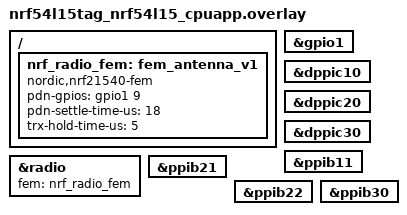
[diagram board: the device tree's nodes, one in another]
/*
 * Copyright (c) 2026 Nordic Semiconductor ASA
 *
 * SPDX-License-Identifier: LicenseRef-Nordic-5-Clause
 */

/*
 * Drive the SKY13348 antenna switch V1 line from MPSL instead of holding it
 * statically high, so it is only asserted around radio TX/RX windows.
 *
 * The nRF21540 FEM driver is reused here purely for its PDN pin, which is the
 * only FEM output asserted for both TX and RX. No nRF21540 is present, so the
 * PA/LNA pins are omitted and all gains are zeroed in the board .conf.
 */

/* Release P1.09 from the board's static hog so GPIOTE can drive it. */
&gpio1 {
	/delete-node/ antenna_switch_v1;
};

/ {
	nrf_radio_fem: fem_antenna_v1 {
		compatible = "nordic,nrf21540-fem";
		pdn-gpios = <&gpio1 9 GPIO_ACTIVE_HIGH>;
		pdn-settle-time-us = <18>;
		trx-hold-time-us = <5>;
	};
};

&radio {
	fem = <&nrf_radio_fem>;
};

/* MPSL FEM needs these on nRF54L; they default to "disabled". */
&dppic10 {
	status = "okay";
};

&dppic20 {
	status = "okay";
};

&dppic30 {
	status = "okay";
};

&ppib11 {
	status = "okay";
};

&ppib21 {
	status = "okay";
};

&ppib22 {
	status = "okay";
};

&ppib30 {
	status = "okay";
};
